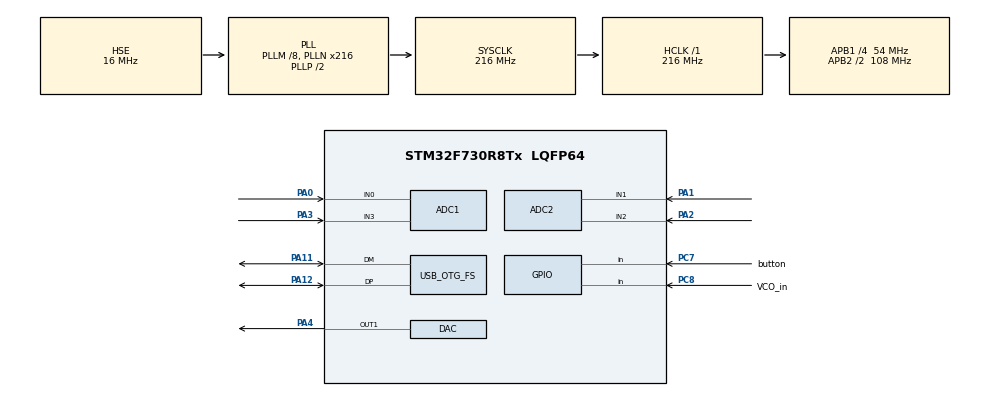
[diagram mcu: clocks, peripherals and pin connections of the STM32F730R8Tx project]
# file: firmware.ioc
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ADC1.Channel-0\#ChannelRegularConversion=ADC_CHANNEL_0
ADC1.Channel-1\#ChannelRegularConversion=ADC_CHANNEL_3
ADC1.ContinuousConvMode=ENABLE
ADC1.DMAContinuousRequests=ENABLE
ADC1.NbrOfConversion=2
ADC1.NbrOfConversionFlag=1
ADC1.Rank-0\#ChannelRegularConversion=1
ADC1.Rank-1\#ChannelRegularConversion=2
ADC1.SamplingTime-0\#ChannelRegularConversion=ADC_SAMPLETIME_3CYCLES
ADC1.SamplingTime-1\#ChannelRegularConversion=ADC_SAMPLETIME_3CYCLES
ADC1.master=1
ADC2.Channel-1\#ChannelRegularConversion=ADC_CHANNEL_1
ADC2.Channel-2\#ChannelRegularConversion=ADC_CHANNEL_2
ADC2.ContinuousConvMode=ENABLE
ADC2.DMAContinuousRequests=ENABLE
ADC2.NbrOfConversion=2
ADC2.NbrOfConversionFlag=1
ADC2.Rank-1\#ChannelRegularConversion=1
ADC2.Rank-2\#ChannelRegularConversion=2
ADC2.SamplingTime-1\#ChannelRegularConversion=ADC_SAMPLETIME_3CYCLES
ADC2.SamplingTime-2\#ChannelRegularConversion=ADC_SAMPLETIME_3CYCLES
CORTEX_M7.AccessPermission_S-Cortex_Memory_Protection_Unit_Region1_Settings_S=MPU_REGION_FULL_ACCESS
CORTEX_M7.AccessPermission_S-Cortex_Memory_Protection_Unit_Region2_Settings_S=MPU_REGION_FULL_ACCESS
CORTEX_M7.AccessPermission_Spec=MPU_REGION_FULL_ACCESS
CORTEX_M7.BaseAddress_S-Cortex_Memory_Protection_Unit_Region1_Settings_S=0x08000000
CORTEX_M7.BaseAddress_S-Cortex_Memory_Protection_Unit_Region2_Settings_S=0x40000000
CORTEX_M7.BaseAddress_Spec=0x20000000
CORTEX_M7.DisableExec_Spec=MPU_INSTRUCTION_ACCESS_ENABLE
CORTEX_M7.Enable_S-Cortex_Memory_Protection_Unit_Region1_Settings_S=MPU_REGION_ENABLE
CORTEX_M7.Enable_S-Cortex_Memory_Protection_Unit_Region2_Settings_S=MPU_REGION_ENABLE
CORTEX_M7.IsCacheable_S-Cortex_Memory_Protection_Unit_Region1_Settings_S=MPU_ACCESS_CACHEABLE
CORTEX_M7.IsCacheable_S-Cortex_Memory_Protection_Unit_Region2_Settings_S=MPU_ACCESS_CACHEABLE
CORTEX_M7.IsCacheable_Spec=MPU_ACCESS_CACHEABLE
CORTEX_M7.IsShareable_S-Cortex_Memory_Protection_Unit_Region2_Settings_S=MPU_ACCESS_SHAREABLE
CORTEX_M7.Size_S-Cortex_Memory_Protection_Unit_Region1_Settings_S=MPU_REGION_SIZE_1MB
CORTEX_M7.Size_S-Cortex_Memory_Protection_Unit_Region2_Settings_S=MPU_REGION_SIZE_512MB
CORTEX_M7.Size_Spec=MPU_REGION_SIZE_8KB
CORTEX_M7.SubRegionDisable_Spec=0x00
CORTEX_M7.default_mode_Activation=1
DAC.DAC_OutputBuffer=DAC_OUTPUTBUFFER_DISABLE
DAC.DAC_Trigger=DAC_TRIGGER_T6_TRGO
Dma.ADC1.0.Direction=DMA_PERIPH_TO_MEMORY
Dma.ADC1.0.FIFOMode=DMA_FIFOMODE_DISABLE
Dma.ADC1.0.Instance=DMA2_Stream0
Dma.ADC1.0.MemDataAlignment=DMA_MDATAALIGN_HALFWORD
Dma.ADC1.0.MemInc=DMA_MINC_ENABLE
Dma.ADC1.0.Mode=DMA_CIRCULAR
Dma.ADC1.0.PeriphDataAlignment=DMA_PDATAALIGN_HALFWORD
Dma.ADC1.0.PeriphInc=DMA_PINC_DISABLE
Dma.ADC1.0.Priority=DMA_PRIORITY_LOW
Dma.ADC2.1.Direction=DMA_PERIPH_TO_MEMORY
Dma.ADC2.1.FIFOMode=DMA_FIFOMODE_DISABLE
Dma.ADC2.1.Instance=DMA2_Stream2
Dma.ADC2.1.MemDataAlignment=DMA_MDATAALIGN_HALFWORD
Dma.ADC2.1.MemInc=DMA_MINC_ENABLE
Dma.ADC2.1.Mode=DMA_CIRCULAR
Dma.ADC2.1.PeriphDataAlignment=DMA_PDATAALIGN_HALFWORD
Dma.ADC2.1.PeriphInc=DMA_PINC_DISABLE
Dma.ADC2.1.Priority=DMA_PRIORITY_LOW
Dma.DAC1.2.Direction=DMA_MEMORY_TO_PERIPH
Dma.DAC1.2.FIFOMode=DMA_FIFOMODE_DISABLE
Dma.DAC1.2.Instance=DMA1_Stream5
Dma.DAC1.2.MemDataAlignment=DMA_MDATAALIGN_HALFWORD
Dma.DAC1.2.MemInc=DMA_MINC_ENABLE
Dma.DAC1.2.Mode=DMA_CIRCULAR
Dma.DAC1.2.PeriphDataAlignment=DMA_PDATAALIGN_HALFWORD
Dma.DAC1.2.PeriphInc=DMA_PINC_DISABLE
Dma.DAC1.2.Priority=DMA_PRIORITY_LOW
Dma.Request0=ADC1
Dma.Request1=ADC2
Dma.Request2=DAC1
FREERTOS.Tasks01=defaultTask,24,256,StartDefaultTask,Default,NULL,Dynamic,NULL,NULL
Mcu.Family=STM32F7
Mcu.Name=STM32F730R8Tx
Mcu.Package=LQFP64
NVIC.DMA1_Stream5_IRQn=true\:5\:0\:false\:false\:true\:true\:false\:true\:true
NVIC.DMA2_Stream0_IRQn=true\:5\:0\:false\:false\:true\:true\:false\:true\:true
NVIC.DMA2_Stream2_IRQn=true\:5\:0\:false\:false\:true\:true\:false\:true\:true
NVIC.OTG_FS_IRQn=true\:5\:0\:false\:false\:true\:true\:false\:true\:true
NVIC.PriorityGroup=NVIC_PRIORITYGROUP_4
NVIC.TIM4_IRQn=true\:15\:0\:false\:false\:true\:false\:false\:true\:true
NVIC.TimeBase=TIM4_IRQn
NVIC.TimeBaseIP=TIM4
PA0-WKUP.Signal=ADCx_IN0
PA1.Signal=ADCx_IN1
PA11.Mode=Device_Only
PA11.Signal=USB_OTG_FS_DM
PA12.Mode=Device_Only
PA12.Signal=USB_OTG_FS_DP
PA13.Mode=Serial_Wire
PA13.Signal=SYS_JTMS-SWDIO
PA14.Mode=Serial_Wire
PA14.Signal=SYS_JTCK-SWCLK
PA2.Signal=ADCx_IN2
PA3.Signal=ADCx_IN3
PA4.Signal=COMP_DAC1_group
PC7.GPIO_Label=button
PC7.GPIO_PuPd=GPIO_PULLUP
PC7.Signal=GPIO_Input
PC8.GPIO_Label=VCO_in
PC8.Signal=GPIO_Input
PH0-OSC_IN.Mode=HSE-External-Oscillator
PH0-OSC_IN.Signal=RCC_OSC_IN
PH1-OSC_OUT.Mode=HSE-External-Oscillator
PH1-OSC_OUT.Signal=RCC_OSC_OUT
ProjectManager.HeapSize=0x200
ProjectManager.StackSize=0x400
ProjectManager.TargetToolchain=CMake
RCC.AHBFreq_Value=216000000
RCC.APB1CLKDivider=RCC_HCLK_DIV4
RCC.APB1Freq_Value=54000000
RCC.APB1TimFreq_Value=108000000
RCC.APB2CLKDivider=RCC_HCLK_DIV2
RCC.APB2Freq_Value=108000000
RCC.APB2TimFreq_Value=216000000
RCC.CortexFreq_Value=216000000
RCC.HCLKFreq_Value=216000000
RCC.HSE_VALUE=16000000
RCC.HSI_VALUE=16000000
RCC.LSE_VALUE=32768
RCC.PLLM=8
RCC.PLLN=216
RCC.PLLQ=9
RCC.SYSCLKFreq_VALUE=216000000
RCC.SYSCLKSource=RCC_SYSCLKSOURCE_PLLCLK
RCC.USBFreq_Value=48000000
RCC.VCOOutputFreq_Value=432000000
SH.ADCx_IN0.0=ADC1_IN0,IN0
SH.ADCx_IN1.0=ADC2_IN1,IN1
SH.ADCx_IN2.0=ADC2_IN2,IN2
SH.ADCx_IN3.0=ADC1_IN3,IN3
SH.COMP_DAC1_group.0=DAC_OUT1,DAC_OUT1
TIM6.TIM_MasterOutputTrigger=TIM_TRGO_ENABLE
USB_DEVICE.CLASS_NAME_FS=CDC
USB_DEVICE.VirtualMode-CDC_FS=Cdc
USB_DEVICE.VirtualModeFS=Cdc_FS
USB_OTG_FS.VirtualMode=Device_Only
VP_FREERTOS_VS_CMSIS_V2.Mode=CMSIS_V2
VP_SYS_VS_tim4.Mode=TIM4
VP_TIM5_VS_ClockSourceITR.Mode=TriggerSource_ITR1
VP_TIM6_VS_ClockSourceINT.Mode=Enable_Timer
VP_USB_DEVICE_VS_USB_DEVICE_CDC_FS.Mode=CDC_FS
board=custom

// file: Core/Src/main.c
/* USER CODE BEGIN Header */
/**
  ******************************************************************************
  * @file           : main.c
  * @brief          : Main program body
  ******************************************************************************
  * @attention
  *
  * Copyright (c) 2025 STMicroelectronics.
  * All rights reserved.
  *
  * This software is licensed under terms that can be found in the LICENSE file
  * in the root directory of this software component.
  * If no LICENSE file comes with this software, it is provided AS-IS.
  *
  ******************************************************************************
  */
/* USER CODE END Header */
#include "main.h"
#include "cmsis_os.h"
#include "usb_device.h"

/* USER CODE BEGIN Includes */
#include "adc.h"
/* USER CODE END Includes */

ADC_HandleTypeDef hadc1;
ADC_HandleTypeDef hadc2;
DMA_HandleTypeDef hdma_adc1;
DMA_HandleTypeDef hdma_adc2;

DAC_HandleTypeDef hdac;
DMA_HandleTypeDef hdma_dac1;

TIM_HandleTypeDef htim5;
TIM_HandleTypeDef htim6;

/* Definitions for defaultTask */
osThreadId_t defaultTaskHandle;
const osThreadAttr_t defaultTask_attributes = {
  .name = "defaultTask",
  .stack_size = 256 * 4,
  .priority = (osPriority_t) osPriorityNormal,
};
/* USER CODE BEGIN PV */
// adc section
osThreadId_t adcTaskHandle;
const osThreadAttr_t adcTask_attributes = {
  .name = "adcTask",
  .stack_size = 128 * 4,
  .priority = (osPriority_t) osPriorityNormal,
};
/* USER CODE END PV */

void SystemClock_Config(void);
static void MPU_Config(void);
static void MX_GPIO_Init(void);
static void MX_DMA_Init(void);
static void MX_ADC1_Init(void);
static void MX_ADC2_Init(void);
static void MX_DAC_Init(void);
static void MX_TIM5_Init(void);
static void MX_TIM6_Init(void);
void StartDefaultTask(void *argument);

int main(void)
{

  /* MPU Configuration--------------------------------------------------------*/
  MPU_Config();

  /* MCU Configuration--------------------------------------------------------*/

  /* Reset of all peripherals, Initializes the Flash interface and the Systick. */
  HAL_Init();

  /* Configure the system clock */
  SystemClock_Config();

  /* Initialize all configured peripherals */
  MX_GPIO_Init();
  MX_DMA_Init();
  MX_ADC1_Init();
  MX_ADC2_Init();
  MX_DAC_Init();
  MX_TIM5_Init();
  MX_TIM6_Init();

  /* Init scheduler */
  osKernelInitialize();

  /* Create the thread(s) */
  /* creation of defaultTask */
  defaultTaskHandle = osThreadNew(StartDefaultTask, NULL, &defaultTask_attributes);

  /* Start scheduler */
  osKernelStart();

  /* We should never get here as control is now taken by the scheduler */

  /* Infinite loop */
  while (1)
  {

  }
}

void SystemClock_Config(void)
{
  RCC_OscInitTypeDef RCC_OscInitStruct = {0};
  RCC_ClkInitTypeDef RCC_ClkInitStruct = {0};

  /** Configure the main internal regulator output voltage
  */
  __HAL_RCC_PWR_CLK_ENABLE();
  __HAL_PWR_VOLTAGESCALING_CONFIG(PWR_REGULATOR_VOLTAGE_SCALE1);

  /** Initializes the RCC Oscillators according to the specified parameters
  * in the RCC_OscInitTypeDef structure.
  */
  RCC_OscInitStruct.OscillatorType = RCC_OSCILLATORTYPE_HSE;
  RCC_OscInitStruct.HSEState = RCC_HSE_ON;
  RCC_OscInitStruct.PLL.PLLState = RCC_PLL_ON;
  RCC_OscInitStruct.PLL.PLLSource = RCC_PLLSOURCE_HSE;
  RCC_OscInitStruct.PLL.PLLM = 8;
  RCC_OscInitStruct.PLL.PLLN = 216;
  RCC_OscInitStruct.PLL.PLLP = RCC_PLLP_DIV2;
  RCC_OscInitStruct.PLL.PLLQ = 9;
  if (HAL_RCC_OscConfig(&RCC_OscInitStruct) != HAL_OK)
  {
    Error_Handler();
  }

  /** Activate the Over-Drive mode
  */
  if (HAL_PWREx_EnableOverDrive() != HAL_OK)
  {
    Error_Handler();
  }

  /** Initializes the CPU, AHB and APB buses clocks
  */
  RCC_ClkInitStruct.ClockType = RCC_CLOCKTYPE_HCLK|RCC_CLOCKTYPE_SYSCLK
                              |RCC_CLOCKTYPE_PCLK1|RCC_CLOCKTYPE_PCLK2;
  RCC_ClkInitStruct.SYSCLKSource = RCC_SYSCLKSOURCE_PLLCLK;
  RCC_ClkInitStruct.AHBCLKDivider = RCC_SYSCLK_DIV1;
  RCC_ClkInitStruct.APB1CLKDivider = RCC_HCLK_DIV4;
  RCC_ClkInitStruct.APB2CLKDivider = RCC_HCLK_DIV2;

  if (HAL_RCC_ClockConfig(&RCC_ClkInitStruct, FLASH_LATENCY_7) != HAL_OK)
  {
    Error_Handler();
  }
}

static void MX_ADC1_Init(void)
{

  ADC_ChannelConfTypeDef sConfig = {0};

  /** Configure the global features of the ADC (Clock, Resolution, Data Alignment and number of conversion)
  */
  hadc1.Instance = ADC1;
  hadc1.Init.ClockPrescaler = ADC_CLOCK_SYNC_PCLK_DIV4;
  hadc1.Init.Resolution = ADC_RESOLUTION_12B;
  hadc1.Init.ScanConvMode = ADC_SCAN_ENABLE;
  hadc1.Init.ContinuousConvMode = ENABLE;
  hadc1.Init.DiscontinuousConvMode = DISABLE;
  hadc1.Init.ExternalTrigConvEdge = ADC_EXTERNALTRIGCONVEDGE_NONE;
  hadc1.Init.ExternalTrigConv = ADC_SOFTWARE_START;
  hadc1.Init.DataAlign = ADC_DATAALIGN_RIGHT;
  hadc1.Init.NbrOfConversion = 2;
  hadc1.Init.DMAContinuousRequests = ENABLE;
  hadc1.Init.EOCSelection = ADC_EOC_SINGLE_CONV;
  if (HAL_ADC_Init(&hadc1) != HAL_OK)
  {
    Error_Handler();
  }

  /** Configure for the selected ADC regular channel its corresponding rank in the sequencer and its sample time.
  */
  sConfig.Channel = ADC_CHANNEL_0;
  sConfig.Rank = ADC_REGULAR_RANK_1;
  sConfig.SamplingTime = ADC_SAMPLETIME_3CYCLES;
  if (HAL_ADC_ConfigChannel(&hadc1, &sConfig) != HAL_OK)
  {
    Error_Handler();
  }

  /** Configure for the selected ADC regular channel its corresponding rank in the sequencer and its sample time.
  */
  sConfig.Channel = ADC_CHANNEL_3;
  sConfig.Rank = ADC_REGULAR_RANK_2;
  if (HAL_ADC_ConfigChannel(&hadc1, &sConfig) != HAL_OK)
  {
    Error_Handler();
  }

}

static void MX_ADC2_Init(void)
{

  ADC_ChannelConfTypeDef sConfig = {0};

  /** Configure the global features of the ADC (Clock, Resolution, Data Alignment and number of conversion)
  */
  hadc2.Instance = ADC2;
  hadc2.Init.ClockPrescaler = ADC_CLOCK_SYNC_PCLK_DIV4;
  hadc2.Init.Resolution = ADC_RESOLUTION_12B;
  hadc2.Init.ScanConvMode = ADC_SCAN_ENABLE;
  hadc2.Init.ContinuousConvMode = ENABLE;
  hadc2.Init.DiscontinuousConvMode = DISABLE;
  hadc2.Init.ExternalTrigConvEdge = ADC_EXTERNALTRIGCONVEDGE_NONE;
  hadc2.Init.ExternalTrigConv = ADC_SOFTWARE_START;
  hadc2.Init.DataAlign = ADC_DATAALIGN_RIGHT;
  hadc2.Init.NbrOfConversion = 2;
  hadc2.Init.DMAContinuousRequests = ENABLE;
  hadc2.Init.EOCSelection = ADC_EOC_SINGLE_CONV;
  if (HAL_ADC_Init(&hadc2) != HAL_OK)
  {
    Error_Handler();
  }

  /** Configure for the selected ADC regular channel its corresponding rank in the sequencer and its sample time.
  */
  sConfig.Channel = ADC_CHANNEL_1;
  sConfig.Rank = ADC_REGULAR_RANK_1;
  sConfig.SamplingTime = ADC_SAMPLETIME_3CYCLES;
  if (HAL_ADC_ConfigChannel(&hadc2, &sConfig) != HAL_OK)
  {
    Error_Handler();
  }

  /** Configure for the selected ADC regular channel its corresponding rank in the sequencer and its sample time.
  */
  sConfig.Channel = ADC_CHANNEL_2;
  sConfig.Rank = ADC_REGULAR_RANK_2;
  if (HAL_ADC_ConfigChannel(&hadc2, &sConfig) != HAL_OK)
  {
    Error_Handler();
  }

}

static void MX_DAC_Init(void)
{

  DAC_ChannelConfTypeDef sConfig = {0};

  /** DAC Initialization
  */
  hdac.Instance = DAC;
  if (HAL_DAC_Init(&hdac) != HAL_OK)
  {
    Error_Handler();
  }

  /** DAC channel OUT1 config
  */
  sConfig.DAC_Trigger = DAC_TRIGGER_T6_TRGO;
  sConfig.DAC_OutputBuffer = DAC_OUTPUTBUFFER_DISABLE;
  if (HAL_DAC_ConfigChannel(&hdac, &sConfig, DAC_CHANNEL_1) != HAL_OK)
  {
    Error_Handler();
  }

}

static void MX_TIM5_Init(void)
{

  TIM_SlaveConfigTypeDef sSlaveConfig = {0};
  TIM_MasterConfigTypeDef sMasterConfig = {0};

  htim5.Instance = TIM5;
  htim5.Init.Prescaler = 0;
  htim5.Init.CounterMode = TIM_COUNTERMODE_UP;
  htim5.Init.Period = 4294967295;
  htim5.Init.ClockDivision = TIM_CLOCKDIVISION_DIV1;
  htim5.Init.AutoReloadPreload = TIM_AUTORELOAD_PRELOAD_DISABLE;
  if (HAL_TIM_Base_Init(&htim5) != HAL_OK)
  {
    Error_Handler();
  }
  sSlaveConfig.SlaveMode = TIM_SLAVEMODE_DISABLE;
  sSlaveConfig.InputTrigger = TIM_TS_ITR1;
  if (HAL_TIM_SlaveConfigSynchro(&htim5, &sSlaveConfig) != HAL_OK)
  {
    Error_Handler();
  }
  sMasterConfig.MasterOutputTrigger = TIM_TRGO_RESET;
  sMasterConfig.MasterSlaveMode = TIM_MASTERSLAVEMODE_DISABLE;
  if (HAL_TIMEx_MasterConfigSynchronization(&htim5, &sMasterConfig) != HAL_OK)
  {
    Error_Handler();
  }

}

static void MX_TIM6_Init(void)
{

  TIM_MasterConfigTypeDef sMasterConfig = {0};

  htim6.Instance = TIM6;
  htim6.Init.Prescaler = 0;
  htim6.Init.CounterMode = TIM_COUNTERMODE_UP;
  htim6.Init.Period = 65535;
  htim6.Init.AutoReloadPreload = TIM_AUTORELOAD_PRELOAD_DISABLE;
  if (HAL_TIM_Base_Init(&htim6) != HAL_OK)
  {
    Error_Handler();
  }
  sMasterConfig.MasterOutputTrigger = TIM_TRGO_ENABLE;
  sMasterConfig.MasterSlaveMode = TIM_MASTERSLAVEMODE_DISABLE;
  if (HAL_TIMEx_MasterConfigSynchronization(&htim6, &sMasterConfig) != HAL_OK)
  {
    Error_Handler();
  }

}

static void MX_DMA_Init(void)
{

  /* DMA controller clock enable */
  __HAL_RCC_DMA2_CLK_ENABLE();
  __HAL_RCC_DMA1_CLK_ENABLE();

  /* DMA interrupt init */
  /* DMA1_Stream5_IRQn interrupt configuration */
  HAL_NVIC_SetPriority(DMA1_Stream5_IRQn, 5, 0);
  HAL_NVIC_EnableIRQ(DMA1_Stream5_IRQn);
  /* DMA2_Stream0_IRQn interrupt configuration */
  HAL_NVIC_SetPriority(DMA2_Stream0_IRQn, 5, 0);
  HAL_NVIC_EnableIRQ(DMA2_Stream0_IRQn);
  /* DMA2_Stream2_IRQn interrupt configuration */
  HAL_NVIC_SetPriority(DMA2_Stream2_IRQn, 5, 0);
  HAL_NVIC_EnableIRQ(DMA2_Stream2_IRQn);

}

static void MX_GPIO_Init(void)
{
  GPIO_InitTypeDef GPIO_InitStruct = {0};

  /* GPIO Ports Clock Enable */
  __HAL_RCC_GPIOH_CLK_ENABLE();
  __HAL_RCC_GPIOA_CLK_ENABLE();
  __HAL_RCC_GPIOC_CLK_ENABLE();

  /*Configure GPIO pin : button_Pin */
  GPIO_InitStruct.Pin = button_Pin;
  GPIO_InitStruct.Mode = GPIO_MODE_INPUT;
  GPIO_InitStruct.Pull = GPIO_PULLUP;
  HAL_GPIO_Init(button_GPIO_Port, &GPIO_InitStruct);

  /*Configure GPIO pin : VCO_in_Pin */
  GPIO_InitStruct.Pin = VCO_in_Pin;
  GPIO_InitStruct.Mode = GPIO_MODE_INPUT;
  GPIO_InitStruct.Pull = GPIO_NOPULL;
  HAL_GPIO_Init(VCO_in_GPIO_Port, &GPIO_InitStruct);

}

void StartDefaultTask(void *argument)
{
  /* init code for USB_DEVICE */
  MX_USB_DEVICE_Init();
  for(;;)
  {
    osDelay(1);
  }
}

 /* MPU Configuration */

void MPU_Config(void)
{
  MPU_Region_InitTypeDef MPU_InitStruct = {0};

  /* Disables the MPU */
  HAL_MPU_Disable();

  /** Initializes and configures the Region and the memory to be protected
  */
  MPU_InitStruct.Enable = MPU_REGION_ENABLE;
  MPU_InitStruct.Number = MPU_REGION_NUMBER0;
  MPU_InitStruct.BaseAddress = 0x20000000;
  MPU_InitStruct.Size = MPU_REGION_SIZE_8KB;
  MPU_InitStruct.SubRegionDisable = 0x00;
  MPU_InitStruct.TypeExtField = MPU_TEX_LEVEL0;
  MPU_InitStruct.AccessPermission = MPU_REGION_FULL_ACCESS;
  MPU_InitStruct.DisableExec = MPU_INSTRUCTION_ACCESS_ENABLE;
  MPU_InitStruct.IsShareable = MPU_ACCESS_SHAREABLE;
  MPU_InitStruct.IsCacheable = MPU_ACCESS_CACHEABLE;
  MPU_InitStruct.IsBufferable = MPU_ACCESS_NOT_BUFFERABLE;

  HAL_MPU_ConfigRegion(&MPU_InitStruct);

  /** Initializes and configures the Region and the memory to be protected
  */
  MPU_InitStruct.Number = MPU_REGION_NUMBER1;
  MPU_InitStruct.BaseAddress = 0x08000000;
  MPU_InitStruct.Size = MPU_REGION_SIZE_1MB;
  MPU_InitStruct.SubRegionDisable = 0x0;
  MPU_InitStruct.IsShareable = MPU_ACCESS_NOT_SHAREABLE;

  HAL_MPU_ConfigRegion(&MPU_InitStruct);

  /** Initializes and configures the Region and the memory to be protected
  */
  MPU_InitStruct.Number = MPU_REGION_NUMBER2;
  MPU_InitStruct.BaseAddress = 0x40000000;
  MPU_InitStruct.Size = MPU_REGION_SIZE_512MB;
  MPU_InitStruct.IsShareable = MPU_ACCESS_SHAREABLE;

  HAL_MPU_ConfigRegion(&MPU_InitStruct);
  /* Enables the MPU */
  HAL_MPU_Enable(MPU_PRIVILEGED_DEFAULT);

}

void HAL_TIM_PeriodElapsedCallback(TIM_HandleTypeDef *htim)
{
  if (htim->Instance == TIM4)
  {
    HAL_IncTick();
  }
}

void Error_Handler(void)
{
  __disable_irq();
  while (1)
  {
  }
}
